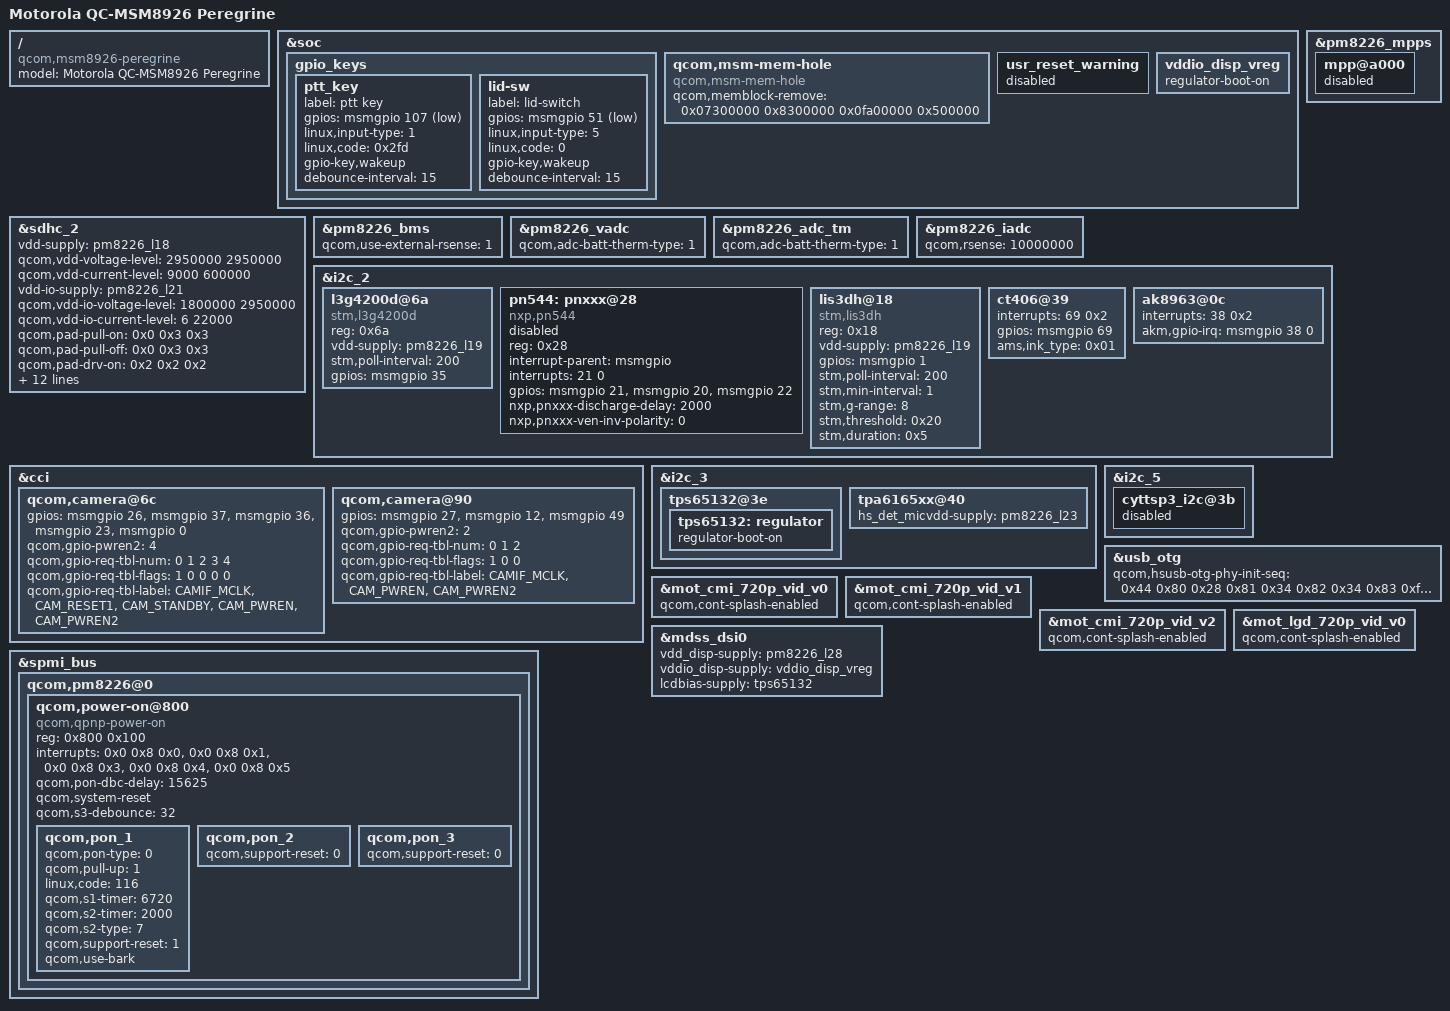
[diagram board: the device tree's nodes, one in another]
/* Copyright (c) 2013, The Linux Foundation. All rights reserved.
 * Copyright (c) 2013 Motorola Mobility LLC
 *
 * This program is free software; you can redistribute it and/or modify
 * it under the terms of the GNU General Public License version 2 and
 * only version 2 as published by the Free Software Foundation.
 *
 * This program is distributed in the hope that it will be useful,
 * but WITHOUT ANY WARRANTY; without even the implied warranty of
 * MERCHANTABILITY or FITNESS FOR A PARTICULAR PURPOSE.  See the
 * GNU General Public License for more details.
 */

/include/ "msm8226-moto-common.dtsi"
/include/ "msm8226-camera-sensor-falcon.dtsi"
/include/ "msm8226-v1-pm.dtsi"
/include/ "msm8926-peregrine-gpiomux.dtsi"
/include/ "dsi-panel-mot-cmi-720p-video.dtsi"
/include/ "dsi-panel-mot-lgd-720p-video.dtsi"

/ {
	model = "Motorola QC-MSM8926 Peregrine";
	compatible = "qcom,msm8926-peregrine",
		     "qcom,msm8226-moto",
		     "qcom,msm8226";
};

&soc {
	gpio_keys {
		ptt_key {
			label = "ptt key";
			gpios = <&msmgpio 107 0x1>;
			linux,input-type = <1>;
			linux,code = <0x2fd>;
			gpio-key,wakeup;
			debounce-interval = <15>;
		};

		lid-sw {
			label = "lid-switch";
			gpios = <&msmgpio 51 0x1>;
			linux,input-type = <5>;
			linux,code = <0>;
			gpio-key,wakeup;
			debounce-interval = <15>;
		};
	};

	qcom,msm-mem-hole {
		compatible = "qcom,msm-mem-hole";
		qcom,memblock-remove = <0x07300000 0x8300000
					0x0fa00000 0x500000>; /* Address and size of the hole */
	};

	usr_reset_warning {
		status = "disabled";
	};

	vddio_disp_vreg: vddio_disp_vreg {
		regulator-boot-on;
	};
};

&sdhc_2 {
	vdd-supply = <&pm8226_l18>;
	qcom,vdd-voltage-level = <2950000 2950000>;
	qcom,vdd-current-level = <9000 600000>;

	vdd-io-supply = <&pm8226_l21>;
	qcom,vdd-io-voltage-level = <1800000 2950000>;
	qcom,vdd-io-current-level = <6 22000>;

	qcom,pad-pull-on = <0x0 0x3 0x3>; /* no-pull, pull-up, pull-up */
	qcom,pad-pull-off = <0x0 0x3 0x3>; /* no-pull, pull-up, pull-up */
	qcom,pad-drv-on = <0x2 0x2 0x2>; /* 6mA, 6mA, 6mA */
	qcom,pad-drv-off = <0x0 0x0 0x0>; /* 2mA, 2mA, 2mA */
	qcom,pad-drv-tune = <0x2 0x3 0x1>; /* 6mA, 8mA, 4mA */

	qcom,clk-rates = <400000 23076923 50000000 100000000 120000000>;
	qcom,bus-speed-mode = "SDR12_1p8v", "SDR25_1p8v", "SDR50_1p8v", "DDR_1p8v", "SDR104_1p8v";

	#address-cells = <0>;
	interrupt-parent = <&sdhc_2>;
	interrupts = <0 1 2>;
	#interrupt-cells = <1>;
	interrupt-map-mask = <0xffffffff>;
	interrupt-map = <0 &intc 0 125 0
			1 &intc 0 221 0
			2 &msmgpio 115 0x3>;
	interrupt-names = "hc_irq", "pwr_irq", "status_irq";
	cd-gpios = <&msmgpio 115 0x1>;

	status = "ok";
};

&pm8226_mpps {
	mpp@a000 { /* MPP 1 */
		status = "disabled";
	};
};

&pm8226_bms {
	qcom,use-external-rsense = <1>;
	status = "ok";
};

&pm8226_vadc {
	qcom,adc-batt-therm-type = <1>;
};

&pm8226_adc_tm {
	qcom,adc-batt-therm-type = <1>;
};

&pm8226_iadc {
	qcom,rsense = <10000000>;
};

&i2c_2 {
	l3g4200d@6a {
		compatible = "stm,l3g4200d";
		reg = <0x6a>;
		vdd-supply =  <&pm8226_l19>;
		stm,poll-interval = <200>;
		gpios = <&msmgpio 35 0>; /* DRDY/INT2 */
	};

	pn544: pnxxx@28 {
		compatible = "nxp,pn544";
		reg = <0x28>;
		interrupt-parent = <&msmgpio>;
		interrupts = <21 0>;
		gpios = <&msmgpio 21 0>,     /* IRQ */
			<&msmgpio 20 0>,     /* VEN */
			<&msmgpio 22 0>;     /* Firmware */
		nxp,pnxxx-discharge-delay = <2000>;
		nxp,pnxxx-ven-inv-polarity = <0>;
		status = "disabled";
	};

	lis3dh@18 {
		compatible = "stm,lis3dh";
		reg = <0x18>;
		vdd-supply = <&pm8226_l19>;
		gpios = <&msmgpio 1 0>; /* IRQ */
		stm,poll-interval = <200>;
		stm,min-interval = <1>;
		stm,g-range = <8>;
		stm,threshold = <0x20>;
		stm,duration = <0x5>;
	};

	ct406@39 {
		interrupts = <69 0x2>;
		gpios = <&msmgpio 69 0>;
		ams,ink_type = <0x01>;
	};

	ak8963@0c {
		interrupts = <38 0x2>;
		akm,gpio-irq = <&msmgpio 38 0>;
	};
};

&cci {
	qcom,camera@6c {
		gpios = <&msmgpio 26 0>,
			<&msmgpio 37 0>,
			<&msmgpio 36 0>,
			<&msmgpio 23 0>,
			<&msmgpio 0 0>;
		qcom,gpio-pwren2 = <4>;
		qcom,gpio-req-tbl-num = <0 1 2 3 4>;
		qcom,gpio-req-tbl-flags = <1 0 0 0 0>;
		qcom,gpio-req-tbl-label = "CAMIF_MCLK",
					  "CAM_RESET1",
					  "CAM_STANDBY",
					  "CAM_PWREN",
					  "CAM_PWREN2";
	};

	qcom,camera@90 {
		gpios = <&msmgpio 27 0>,
			<&msmgpio 12 0>,
			<&msmgpio 49 0>;
		qcom,gpio-pwren2 = <2>;
		qcom,gpio-req-tbl-num = <0 1 2>;
		qcom,gpio-req-tbl-flags = <1 0 0>;
		qcom,gpio-req-tbl-label = "CAMIF_MCLK",
					  "CAM_PWREN",
					  "CAM_PWREN2";
	};
};

&i2c_3 {
	tps65132@3e {
		tps65132: regulator {
			regulator-boot-on;
		};
	};

	tpa6165xx@40 {
		hs_det_micvdd-supply = <&pm8226_l23>;
	};
};

&i2c_5 {
	cyttsp3_i2c@3b {
		status = "disabled";
	};
};

&usb_otg {
	qcom,hsusb-otg-phy-init-seq =
		<0x44 0x80 0x28 0x81 0x34 0x82 0x34 0x83 0xffffffff>;
};

&mot_cmi_720p_vid_v0 {
	qcom,cont-splash-enabled;
};

&mot_cmi_720p_vid_v1 {
	qcom,cont-splash-enabled;
};

&mot_cmi_720p_vid_v2 {
	qcom,cont-splash-enabled;
};

&mot_lgd_720p_vid_v0 {
	qcom,cont-splash-enabled;
};

&mdss_dsi0 {
	vdd_disp-supply = <&pm8226_l28>;
	vddio_disp-supply = <&vddio_disp_vreg>;
	lcdbias-supply = <&tps65132>;
};

&spmi_bus {
	qcom,pm8226@0 {
		qcom,power-on@800 {
			compatible = "qcom,qpnp-power-on";
			reg = <0x800 0x100>;
			interrupts = <0x0 0x8 0x0>,
				     <0x0 0x8 0x1>,
				     <0x0 0x8 0x3>,
				     <0x0 0x8 0x4>,
				     <0x0 0x8 0x5>;
			interrupt-names = "kpdpwr", "resin", "kpdpwr-bark",
					"resin-bark", "kpdpwr-resin-bark";
			qcom,pon-dbc-delay = <15625>;
			qcom,system-reset;
			qcom,s3-debounce = <32>;

			qcom,pon_1 {
				qcom,pon-type = <0>;
				qcom,pull-up = <1>;
				linux,code = <116>;
				qcom,s1-timer = <6720>;
				qcom,s2-timer = <2000>;
				qcom,s2-type = <7>;
				qcom,support-reset = <1>;
				qcom,use-bark;
			};

			qcom,pon_2 {
				qcom,support-reset = <0>;
			};

			qcom,pon_3 {
				qcom,support-reset = <0>;
			};
		};
	};
};
